# ATSAM4LC2A register map
Vendor: Atmel Corporation; Series: SAM4L; File version: B
CPU: CM4 r0p1, little endian, MPU, no FPU, 4 interrupt priority bits
Registers are 32-bit, write-only, reset 0x0 unless marked. A register's access mark holds for its fields unless they carry their own. Offsets are from the block's base; [hi:lo] are bit positions; {n}, {i} and the like mark numbered series; 'fields as' and 'values as' point back to an identical list.

## LCDCA — LCD Controller
Base 0x40080000; register names take the prefix LCDCA_
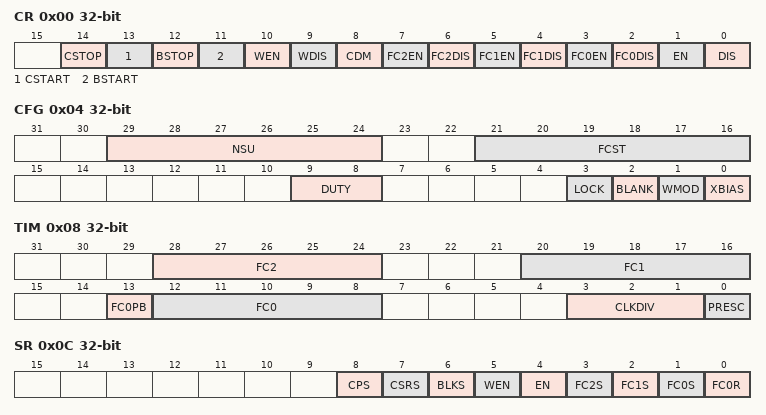
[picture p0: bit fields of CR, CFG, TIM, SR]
0x00 CR — Control Register
  [14] CSTOP — Circular Shift Stop
  [13] CSTART — Circular Shift Start
  [12] BSTOP — Blinking Stop
  [11] BSTART — Blinking Start
  [10] WEN — Wake up Enable
  [9] WDIS — Wake up Disable
  [8] CDM — Clear Display Memory
  [7] FC2EN — Frame Counter 2 Enable
  [6] FC2DIS — Frame Counter 2 Disable
  [5] FC1EN — Frame Counter 1 Enable
  [4] FC1DIS — Frame Counter 1 Disable
  [3] FC0EN — Frame Counter 0 Enable
  [2] FC0DIS — Frame Counter 0 Disable
  [1] EN — Enable
  [0] DIS — Disable
0x04 CFG rw — Configuration Register
  [29:24] NSU — Number of Segment Terminals in Use
  [21:16] FCST — Fine Contrast
  [9:8] DUTY — Duty Select
  [3] LOCK
  [2] BLANK — Blank LCD
  [1] WMOD — Waveform Mode
  [0] XBIAS — External Bias Generation
0x08 TIM rw — Timing Register
  [28:24] FC2 — Frame Counter 2
  [20:16] FC1 — Frame Counter 1
  [13] FC0PB — Frame Counter 0 Prescaler Bypass
  [12:8] FC0 — Frame Counter 0
  [3:1] CLKDIV — LCD Clock Division
  [0] PRESC — LCD Prescaler Select
0x0C SR ro — Status Register
  [8] CPS — Charge Pump Status
  [7] CSRS — Circular Shift Register Status
  [6] BLKS — Blink Status
  [5] WEN — Wake up Status
  [4] EN — LCDCA Status
  [3] FC2S — Frame Counter 2 Status
  [2] FC1S — Frame Counter 1 Status
  [1] FC0S — Frame Counter 0 Status
  [0] FC0R — Frame Counter 0 Rollover
0x10 SCR — Status Clear Register
  [0] FC0R — Frame Counter 0 Rollover
{0x14+8i} DRL{i} rw (i=0..3) — Data Register Low {i}
  [31:0] DATA — Segments Value
{0x18+8i} DRH{i} rw (i=0..3) — Data Register High {i}
  [7:0] DATA — Segments Value
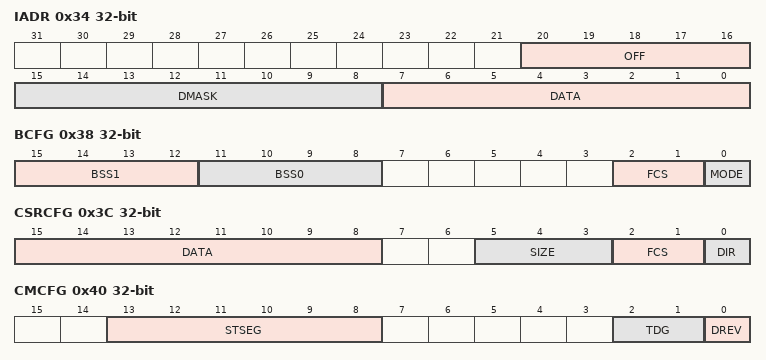
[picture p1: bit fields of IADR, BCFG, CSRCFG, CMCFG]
0x34 IADR — Indirect Access Data Register
  [20:16] OFF — Byte Offset
  [15:8] DMASK — Data Mask
  [7:0] DATA — Segments Value
0x38 BCFG rw — Blink Configuration Register
  [15:12] BSS1 — Blink Segment Selection 1
  [11:8] BSS0 — Blink Segment Selection 0
  [2:1] FCS — Frame Counter Selection
  [0] MODE — Blinking Mode
0x3C CSRCFG rw — Circular Shift Register Configuration
  [15:8] DATA — Circular Shift Register Value
  [5:3] SIZE
  [2:1] FCS — Frame Counter Selection
  [0] DIR — Direction
0x40 CMCFG rw — Character Mapping Configuration Register
  [13:8] STSEG — Start Segment
  [2:1] TDG — Type of Digit
  [0] DREV — Digit Reverse Mode
0x44 CMDR — Character Mapping Data Register
  [6:0] ASCII — ASCII Code
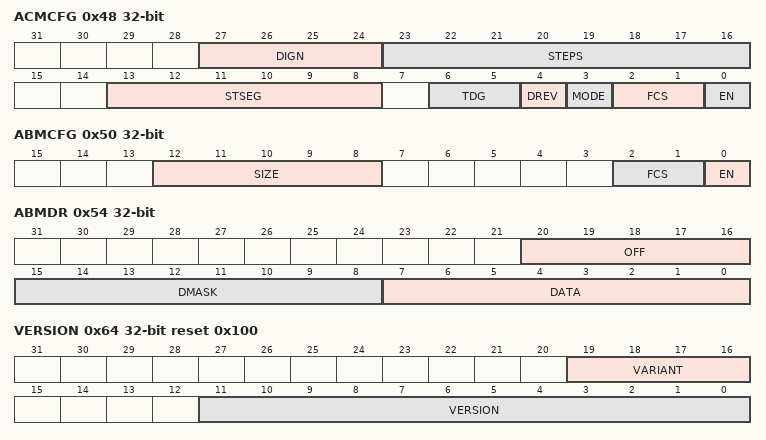
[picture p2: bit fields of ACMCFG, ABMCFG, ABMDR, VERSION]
0x48 ACMCFG rw — Automated Character Mapping Configuration Register
  [27:24] DIGN — Digit Number
  [23:16] STEPS — Scrolling Steps
  [13:8] STSEG — Start Segment
  [6:5] TDG — Type of Digit
  [4] DREV — Digit Reverse
  [3] MODE — Mode (sequential or scrolling)
  [2:1] FCS — Frame Counter Selection
  [0] EN — Enable
0x4C ACMDR — Automated Character Mapping Data Register
  [6:0] ASCII — ASCII Code
0x50 ABMCFG rw — Automated Bit Mapping Configuration Register
  [12:8] SIZE
  [2:1] FCS — Frame Counter Selection
  [0] EN — Enable
0x54 ABMDR — Automated Bit Mapping Data Register
  fields as IADR
0x58 IER — Interrupt Enable Register
  [0] FC0R — Frame Counter 0 Rollover
0x5C IDR — Interrupt Disable Register
  [0] FC0R — Frame Counter 0 Rollover
0x60 IMR ro — Interrupt Mask Register
  [0] FC0R — Frame Counter 0 Rollover
0x64 VERSION ro reset 0x100
  [19:16] VARIANT — Variant Number
  [11:0] VERSION — Version Number

## PARC — Parallel Capture
Base 0x4006C000; register names take the prefix PARC_
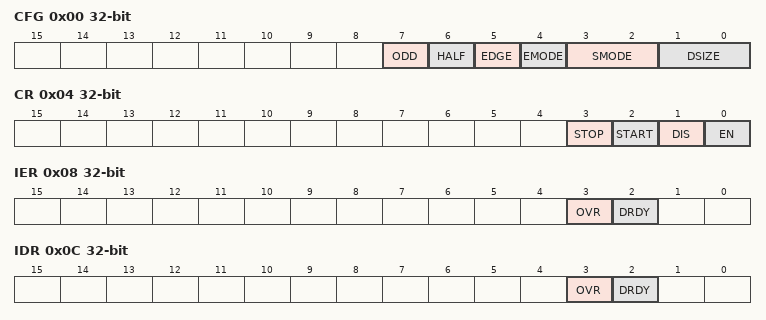
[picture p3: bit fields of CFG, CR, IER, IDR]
0x00 CFG rw — Configuration Register
  [7] ODD — Odd Capture
  [6] HALF — Half Capture
  [5] EDGE — Sampling Edge Select
  [4] EMODE — Events Mode
  [3:2] SMODE — Sampling Mode
  [1:0] DSIZE — Data Size
0x04 CR rw — Control Register
  [3] STOP — Stop Capture
  [2] START wo — Start Capture
  [1] DIS wo — Disable
  [0] EN — Enable
0x08 IER — Interrupt Enable Register
  [3] OVR — Overrun Interrupt Enable
  [2] DRDY — Data Ready Interrupt Enable
0x0C IDR — Interrupt Disable Register
  [3] OVR — Overrun Interrupt Disable
  [2] DRDY — Data Ready Interrupt Disable
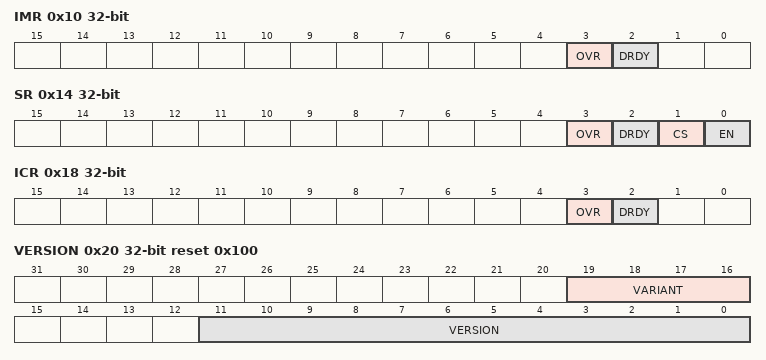
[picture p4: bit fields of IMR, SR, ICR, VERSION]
0x10 IMR ro — Interrupt Mask Register
  [3] OVR — Overrun Interrupt Mask
  [2] DRDY — Data Ready Interrupt Mask
0x14 SR ro — Status Register
  [3] OVR — Overrun Interrupt Status
  [2] DRDY — Data Ready Interrupt Status
  [1] CS — Capture Status
  [0] EN — Enable Status
0x18 ICR — Interrupt Status Clear Register
  [3] OVR — Overrun Interrupt Status Clear
  [2] DRDY — Data Ready Interrupt Status Clear
0x1C RHR ro — Receive Holding Register
  [31:0] CDATA — Captured Data
0x20 VERSION ro reset 0x100
  [19:16] VARIANT — Variant Number
  [11:0] VERSION — Version Number

## Notices in the file
Atmel Microcontroller Software Support
Copyright (c) 2014, Atmel Corporation
All rights reserved.
Redistribution and use in source and binary forms, with or without
modification, are permitted provided that the following condition is met:
- Redistributions of source code must retain the above copyright notice,
this list of conditions and the disclaimer below.
Atmel's name may not be used to endorse or promote products derived from
this software without specific prior written permission.
DISCLAIMER: THIS SOFTWARE IS PROVIDED BY ATMEL "AS IS" AND ANY EXPRESS OR
IMPLIED WARRANTIES, INCLUDING, BUT NOT LIMITED TO, THE IMPLIED WARRANTIES OF
MERCHANTABILITY, FITNESS FOR A PARTICULAR PURPOSE AND NON-INFRINGEMENT ARE
DISCLAIMED. IN NO EVENT SHALL ATMEL BE LIABLE FOR ANY DIRECT, INDIRECT,
INCIDENTAL, SPECIAL, EXEMPLARY, OR CONSEQUENTIAL DAMAGES (INCLUDING, BUT NOT
LIMITED TO, PROCUREMENT OF SUBSTITUTE GOODS OR SERVICES; LOSS OF USE, DATA,
OR PROFITS; OR BUSINESS INTERRUPTION) HOWEVER CAUSED AND ON ANY THEORY OF
LIABILITY, WHETHER IN CONTRACT, STRICT LIABILITY, OR TORT (INCLUDING
NEGLIGENCE OR OTHERWISE) ARISING IN ANY WAY OUT OF THE USE OF THIS SOFTWARE,
EVEN IF ADVISED OF THE POSSIBILITY OF SUCH DAMAGE.
